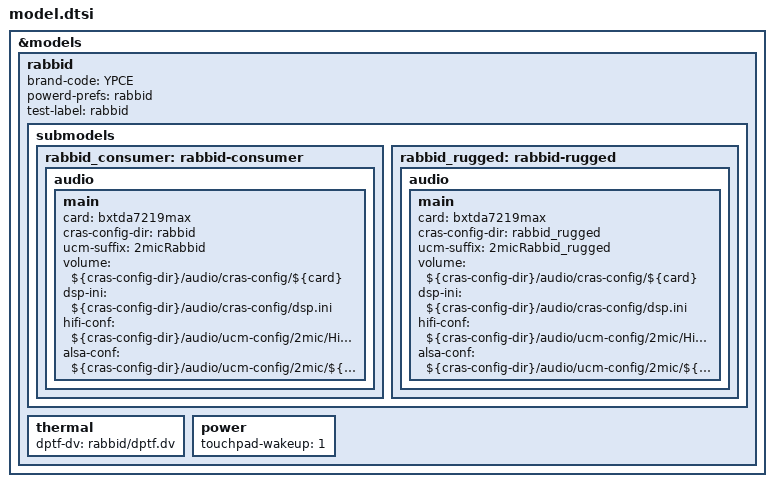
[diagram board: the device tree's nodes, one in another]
/* Copyright 2018 The Chromium OS Authors. All rights reserved.
 *
 * Use of this source code is governed by a BSD-style license that can be
 * found in the LICENSE file.
 */

&models {
	rabbid: rabbid {
		brand-code = "YPCE";
		powerd-prefs = "rabbid";
		test-label = "rabbid";
		submodels {
			rabbid_consumer: rabbid-consumer {
				audio {
					main {
						card = "bxtda7219max";
						cras-config-dir = "rabbid";	
						ucm-suffix = "2micRabbid";	
						volume = "${cras-config-dir}/audio/cras-config/${card}";	
						dsp-ini = "${cras-config-dir}/audio/cras-config/dsp.ini";	
						hifi-conf = "${cras-config-dir}/audio/ucm-config/2mic/HiFi";	
						alsa-conf = "${cras-config-dir}/audio/ucm-config/2mic/${card}.conf";
					};
				};
			};
			rabbid_rugged: rabbid-rugged {
				audio {
					main {
						card = "bxtda7219max";
						cras-config-dir = "rabbid_rugged";
						ucm-suffix = "2micRabbid_rugged";
						volume = "${cras-config-dir}/audio/cras-config/${card}";
						dsp-ini = "${cras-config-dir}/audio/cras-config/dsp.ini";
						hifi-conf = "${cras-config-dir}/audio/ucm-config/2mic/HiFi";
						alsa-conf = "${cras-config-dir}/audio/ucm-config/2mic/${card}.conf";
					};
				};
			};
		};
		thermal {
			dptf-dv = "rabbid/dptf.dv";
		};
		power {
			touchpad-wakeup = "1";
		};
	};
};
